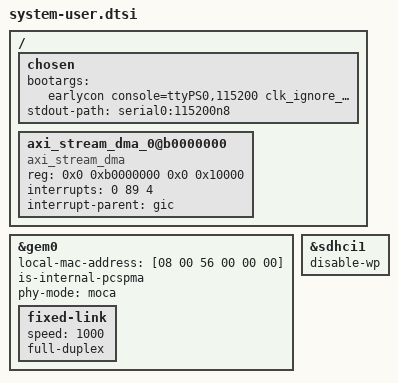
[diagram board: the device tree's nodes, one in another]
/ {
	chosen {
		bootargs = " earlycon console=ttyPS0,115200 clk_ignore_unused root=/dev/ram0 rw";
		stdout-path = "serial0:115200n8";
	};
};
&gem0 {
	local-mac-address = [08 00 56 00 00 00];
	is-internal-pcspma;
	phy-mode = "moca";
	fixed-link {
		speed = <1000>;
		full-duplex;
	};
};
&sdhci1 {
	disable-wp;
};
/ {
	axi_stream_dma_0@b0000000 {
		compatible = "axi_stream_dma";
		reg = <0x0 0xb0000000 0x0 0x10000>;
		interrupts = <0 89 4>;
		interrupt-parent = <&gic>;
	};
};
